# STM32WBAxx register map
File version: 0.2
Registers are 32-bit, read-write, reset 0x0 unless marked. A register's access mark holds for its fields unless they carry their own. Offsets are from the block's base; [hi:lo] are bit positions; {n}, {i} and the like mark numbered series.

## GTZC1_MPCBB1 — GTZC1_MPCBB1 address block description
Base 0x40032C00
Same registers: GTZC1_MPCBB2 0x40033000, SEC_GTZC1_MPCBB1 0x50032C00, SEC_GTZC1_MPCBB2 0x50033000
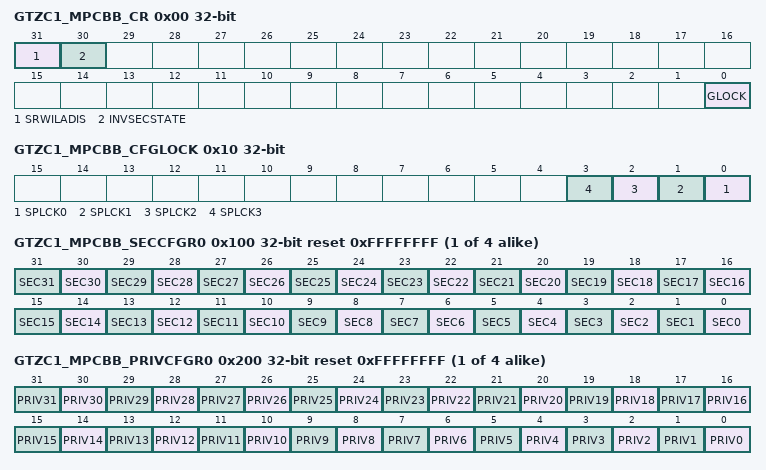
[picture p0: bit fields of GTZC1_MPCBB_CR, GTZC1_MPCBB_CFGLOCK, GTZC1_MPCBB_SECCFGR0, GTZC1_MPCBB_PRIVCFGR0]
0x00 GTZC1_MPCBB_CR — MPCBB control register
  [31] SRWILADIS — secure read/write illegal access disable; This bit disables the detection of an illegal access when a secure read/write transaction access a non-secure blocks of the block-based SRAM (secure fetch on non-secure block is always considered illegal).
    0=enabled, secure read/write acces not allowed on non-secure SRAM block; 1=disabled, secure read/write access allowed on non-secure SRAM block
  [30] INVSECSTATE — SRAM clocks security state; This bit is used to define the internal SRAM clocks control in RCC as secure or not.
    0=SRAM clock is secured if a secure area exists in the MPCBB. It is non secure if there is no secure area.; 1=SRAM clock is non-secure even if a secure area exists in the MPCBB, and secure even if no secure block is set in the MPCBB
  [0] GLOCK — lock the control register of the MPCBB until next reset; This bit is cleared by default and once set, it can not be reset until system reset.
    0=control register not locked; 1=control register locked
0x10 GTZC1_MPCBB_CFGLOCK — GTZC1 SRAMz MPCBB configuration lock register
  [all] fields
    0=GTZC1_MPCBB_SECCFGRn and GTZC1_MPCBB_PRIVCFGRn can be written; 1=Writes to GTZC1_MPCBB_SECCFGRn and GTZC1_MPCBB_PRIVCFGRn are ignored
  [n] SPLCK{n} (n=0..3) — Security/privilege configuration lock super-block; This bit is set by software and can be cleared only by system reset.; note that bit [3:2] are reserved on sales type STM32WBA5xEx for MPCBB1.
{0x100+4i} GTZC1_MPCBB_SECCFGR{i} reset 0xFFFFFFFF (i=0..3) — GTZC1 MPCBB security configuration for super-block {i} register
  [all] fields
    0=Non-secure access only to block y, belonging to super-block n. Secure access is also allowed if the SRWILADIS bit is set in GTZC1_MPCBB_CR.; 1=Secure access only to block y, belonging to super-block n
  [n] SEC{n} (n=0..31) — Security configuration for block y (y = 0 to 31) in super block n Unprivileged write to this bit is ignored if PRIVy bit is set in GTZC1_MPCBB_PRIVCFGRn. Writes are ignored if SPLCKn bit is set in GTZC1_MPCBB_CFGLOCK.
{0x200+4i} GTZC1_MPCBB_PRIVCFGR{i} reset 0xFFFFFFFF (i=0..3) — GTZC1 MPCBB privileged configuration for super-block {i} register
  [all] fields
    0=Privileged and unprivileged access to block y, belonging to super-block n; 1=Only privileged access to block y, belonging to super-block n
  [n] PRIV{n} (n=0..31) — Privileged configuration for block y (y = 0 to 31), belonging to super-block n. Non-secure write to this bit is ignored if SECy bit is set in GTZC1_MPCBB_SECCFGRn. Writes are ignored if SPLCKn bit is set in GTZC1_MPCBB_CFGLOCK.

## GTZC1_MPCBB6 — GTZC1_MPCBB6 address block description
Base 0x40034000
Same registers: SEC_GTZC1_MPCBB6 0x50034000
Registers as GTZC1_MPCBB1, without GTZC1_MPCBB_SECCFGR{n} (n=1..3), GTZC1_MPCBB_PRIVCFGR{n} (n=1..3); these are added or differ:
0x10 GTZC1_MPCBB_CFGLOCK — GTZC1 SRAMz MPCBB configuration lock register
  [0] SPLCK0 — Security/privilege configuration lock super-block; This bit is set by software and can be cleared only by system reset.; note that bit [3:2] are reserved on sales type STM32WBA5xEx for MPCBB1.
    0=GTZC1_MPCBB_SECCFGRn and GTZC1_MPCBB_PRIVCFGRn can be written; 1=Writes to GTZC1_MPCBB_SECCFGRn and GTZC1_MPCBB_PRIVCFGRn are ignored

## WWDG — System window watchdog
Base 0x40002C00
Same registers: SEC_WWDG 0x50002C00
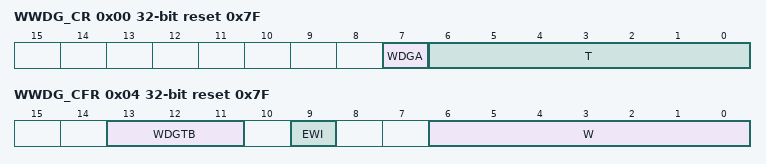
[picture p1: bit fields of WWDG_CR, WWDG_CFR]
0x00 WWDG_CR reset 0x7F — WWDG control register
  [7] WDGA — Activation bit This bit is set by software and only cleared by hardware after a reset. When WDGA = 1, the watchdog can generate a reset.
    0=Watchdog disabled; 1=Watchdog enabled
  [6:0] T — 7-bit counter (MSB to LSB) These bits contain the value of the watchdog counter, decremented every (4096 x 2<sup>WDGTB[2:0]</sup>) PCLK cycles. A reset is produced when it is decremented from 0x40 to 0x3F (T6 becomes cleared).
0x04 WWDG_CFR reset 0x7F — WWDG configuration register
  [13:11] WDGTB — Timer base The timebase of the prescaler can be modified as follows:
    0=CK counter clock (PCLK div 4096) div 1; 1=CK counter clock (PCLK div 4096) div 2; 2=CK counter clock (PCLK div 4096) div 4; 3=CK counter clock (PCLK div 4096) div 8; 4=CK counter clock (PCLK div 4096) div 16; 5=CK counter clock (PCLK div 4096) div 32; 6=CK counter clock (PCLK div 4096) div 64; 7=CK counter clock (PCLK div 4096) div 128
  [9] EWI — Early wakeup interrupt When set, an interrupt occurs whenever the counter reaches the value 0x40. This interrupt is only cleared by hardware after a reset.
  [6:0] W — 7-bit window value These bits contain the window value to be compared with the down-counter.
0x08 WWDG_SR — WWDG status register
  [0] EWIF — Early wakeup interrupt flag This bit is set by hardware when the counter has reached the value 0x40. It must be cleared by software by writing 0. Writing 1 has no effect. This bit is also set if the interrupt is not enabled.
